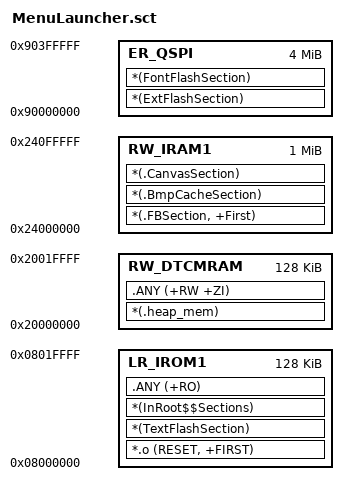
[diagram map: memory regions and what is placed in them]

; *************************************************************
; *** Scatter-Loading Description File generated by uVision ***
; *************************************************************

LR_IROM1 0x08000000 0x20000  {    ; load region size_region
  LR_IROM1 0x08000000  0x20000{
  *.o (RESET, +FIRST)
   *(TextFlashSection)
    *(InRoot$$Sections)
      .ANY (+RO)     
                }
                
     RW_DTCMRAM 0x20000000 0x20000  {  ; RW data
		*(.heap_mem) 
		.ANY (+RW +ZI)
		}
     RW_IRAM1 0x24000000 0x100000  {     ; RW data
        *(.FBSection, +First)
		 *(.BmpCacheSection)
		  *(.CanvasSection)
		
                            }

  }
LR_QSPI 0x90000000 0x400000  {    ; load region size_region
  ER_QSPI 0x90000000 0x400000 {         
  *(ExtFlashSection)
    *(FontFlashSection)           
              }
}



